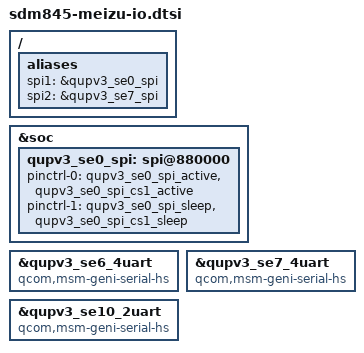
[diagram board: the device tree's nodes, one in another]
/* Copyright (c) 2022, MeizuCustoms enthusiasts
 *
 * This program is free software; you can redistribute it and/or modify
 * it under the terms of the GNU General Public License version 2 and
 * only version 2 as published by the Free Software Foundation.
 *
 * This program is distributed in the hope that it will be useful,
 * but WITHOUT ANY WARRANTY; without even the implied warranty of
 * MERCHANTABILITY or FITNESS FOR A PARTICULAR PURPOSE.  See the
 * GNU General Public License for more details.
 */

/ {
    aliases {
        spi1 = &qupv3_se0_spi;
        spi2 = &qupv3_se7_spi;
    };
};

&soc {
    qupv3_se0_spi: spi@880000 {
        pinctrl-0 = <&qupv3_se0_spi_active &qupv3_se0_spi_cs1_active>;
		pinctrl-1 = <&qupv3_se0_spi_sleep &qupv3_se0_spi_cs1_sleep>;
    };
};

&qupv3_se6_4uart {
    compatible = "qcom,msm-geni-serial-hs", "qcom,msm-geni-uart";
};

&qupv3_se7_4uart {
    compatible = "qcom,msm-geni-serial-hs", "qcom,msm-geni-uart";
};

&qupv3_se10_2uart {
    compatible = "qcom,msm-geni-serial-hs", "qcom,msm-geni-uart";
};
